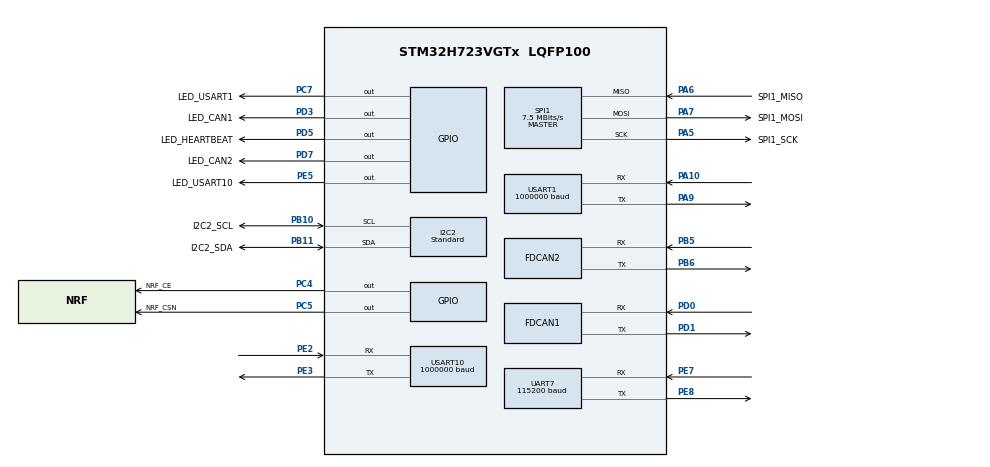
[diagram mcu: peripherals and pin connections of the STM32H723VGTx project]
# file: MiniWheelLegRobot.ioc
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CORTEX_M7.CPU_DCache=Disabled
CORTEX_M7.CPU_ICache=Enabled
Dma.Request0=UART7_RX
Dma.UART7_RX.0.Direction=DMA_PERIPH_TO_MEMORY
Dma.UART7_RX.0.EventEnable=DISABLE
Dma.UART7_RX.0.FIFOMode=DMA_FIFOMODE_DISABLE
Dma.UART7_RX.0.Instance=DMA1_Stream7
Dma.UART7_RX.0.MemDataAlignment=DMA_MDATAALIGN_BYTE
Dma.UART7_RX.0.MemInc=DMA_MINC_ENABLE
Dma.UART7_RX.0.Mode=DMA_NORMAL
Dma.UART7_RX.0.PeriphDataAlignment=DMA_PDATAALIGN_BYTE
Dma.UART7_RX.0.PeriphInc=DMA_PINC_DISABLE
Dma.UART7_RX.0.Polarity=HAL_DMAMUX_REQ_GEN_RISING
Dma.UART7_RX.0.Priority=DMA_PRIORITY_HIGH
Dma.UART7_RX.0.RequestNumber=1
Dma.UART7_RX.0.SignalID=NONE
Dma.UART7_RX.0.SyncEnable=DISABLE
Dma.UART7_RX.0.SyncPolarity=HAL_DMAMUX_SYNC_NO_EVENT
Dma.UART7_RX.0.SyncRequestNumber=1
Dma.UART7_RX.0.SyncSignalID=NONE
FDCAN1.AutoRetransmission=ENABLE
FDCAN1.CalculateBaudRateNominal=1000000
FDCAN1.CalculateTimeBitNominal=1000
FDCAN1.CalculateTimeQuantumNominal=12.5
FDCAN1.DataPrescaler=1
FDCAN1.DataTimeSeg1=59
FDCAN1.DataTimeSeg2=20
FDCAN1.ExtFiltersNbr=0
FDCAN1.MessageRAMOffset=0
FDCAN1.NominalPrescaler=1
FDCAN1.NominalSyncJumpWidth=20
FDCAN1.NominalTimeSeg1=59
FDCAN1.NominalTimeSeg2=20
FDCAN1.DataSyncJumpWidth=20
FDCAN1.RxFifo0ElmtSize=FDCAN_DATA_BYTES_8
FDCAN1.RxFifo0ElmtsNbr=16
FDCAN1.StdFiltersNbr=1
FDCAN1.TxElmtSize=FDCAN_DATA_BYTES_8
FDCAN1.TxFifoQueueElmtsNbr=8
FDCAN2.AutoRetransmission=ENABLE
FDCAN2.CalculateBaudRateNominal=1000000
FDCAN2.CalculateTimeBitNominal=1000
FDCAN2.CalculateTimeQuantumNominal=12.5
FDCAN2.DataPrescaler=1
FDCAN2.DataTimeSeg1=59
FDCAN2.DataTimeSeg2=20
FDCAN2.ExtFiltersNbr=0
FDCAN2.MessageRAMOffset=1280
FDCAN2.NominalPrescaler=1
FDCAN2.NominalSyncJumpWidth=20
FDCAN2.NominalTimeSeg1=59
FDCAN2.NominalTimeSeg2=20
FDCAN2.DataSyncJumpWidth=20
FDCAN2.RxFifo0ElmtSize=FDCAN_DATA_BYTES_8
FDCAN2.RxFifo0ElmtsNbr=16
FDCAN2.StdFiltersNbr=1
FDCAN2.TxElmtSize=FDCAN_DATA_BYTES_8
FDCAN2.TxFifoQueueElmtsNbr=8
FREERTOS.Tasks01=CtrlTask,56,512,StartCtrlTask,As external,NULL,Dynamic,NULL,NULL;CommandTask,40,384,StartCommandTask,As external,NULL,Dynamic,NULL,NULL;MonitorTask,24,384,StartMonitorTask,As external,NULL,Dynamic,NULL,NULL
I2C2.I2C_Speed_Mode=I2C_Standard
I2C2.Timing=0xB0522731
Mcu.Family=STM32H7
Mcu.Name=STM32H723VGTx
Mcu.Package=LQFP100
NVIC.DMA1_Stream7_IRQn=true\:5\:0\:true\:false\:true\:true\:false\:true\:true
NVIC.FDCAN1_IT0_IRQn=true\:5\:0\:true\:false\:true\:true\:true\:true\:true
NVIC.FDCAN2_IT0_IRQn=true\:5\:0\:true\:false\:true\:true\:true\:true\:true
NVIC.PriorityGroup=NVIC_PRIORITYGROUP_4
NVIC.TIM2_IRQn=true\:15\:0\:false\:false\:true\:false\:false\:true\:true
NVIC.TimeBase=TIM2_IRQn
NVIC.TimeBaseIP=TIM2
NVIC.UART7_IRQn=true\:5\:0\:true\:false\:true\:true\:true\:true\:true
PA10.Mode=Asynchronous
PA10.Signal=USART1_RX
PA13(JTMS/SWDIO).GPIO_Label=SWDIO
PA13(JTMS/SWDIO).Mode=Serial_Wire
PA13(JTMS/SWDIO).Signal=DEBUG_JTMS-SWDIO
PA14(JTCK/SWCLK).GPIO_Label=SWCLK
PA14(JTCK/SWCLK).Mode=Serial_Wire
PA14(JTCK/SWCLK).Signal=DEBUG_JTCK-SWCLK
PA5.GPIO_Label=SPI1_SCK
PA5.Mode=Full_Duplex_Master
PA5.Signal=SPI1_SCK
PA6.GPIO_Label=SPI1_MISO
PA6.Mode=Full_Duplex_Master
PA6.Signal=SPI1_MISO
PA7.GPIO_Label=SPI1_MOSI
PA7.Mode=Full_Duplex_Master
PA7.Signal=SPI1_MOSI
PA9.Mode=Asynchronous
PA9.Signal=USART1_TX
PB10.GPIO_Label=I2C2_SCL
PB10.Mode=I2C
PB10.Signal=I2C2_SCL
PB11.GPIO_Label=I2C2_SDA
PB11.Mode=I2C
PB11.Signal=I2C2_SDA
PB5.Mode=FDCAN_Activate
PB5.Signal=FDCAN2_RX
PB6.Mode=FDCAN_Activate
PB6.Signal=FDCAN2_TX
PC4.GPIO_Label=NRF_CE
PC4.GPIO_Speed=GPIO_SPEED_FREQ_HIGH
PC4.PinState=GPIO_PIN_RESET
PC4.Signal=GPIO_Output
PC5.GPIO_Label=NRF_CSN
PC5.GPIO_Speed=GPIO_SPEED_FREQ_HIGH
PC5.PinState=GPIO_PIN_SET
PC5.Signal=GPIO_Output
PC7.GPIO_Label=LED_USART1
PC7.GPIO_Speed=GPIO_SPEED_FREQ_LOW
PC7.PinState=GPIO_PIN_RESET
PC7.Signal=GPIO_Output
PD0.Mode=FDCAN_Activate
PD0.Signal=FDCAN1_RX
PD1.Mode=FDCAN_Activate
PD1.Signal=FDCAN1_TX
PD3.GPIO_Label=LED_CAN1
PD3.GPIO_Speed=GPIO_SPEED_FREQ_LOW
PD3.PinState=GPIO_PIN_RESET
PD3.Signal=GPIO_Output
PD5.GPIO_Label=LED_HEARTBEAT
PD5.GPIO_Speed=GPIO_SPEED_FREQ_LOW
PD5.PinState=GPIO_PIN_RESET
PD5.Signal=GPIO_Output
PD7.GPIO_Label=LED_CAN2
PD7.GPIO_Speed=GPIO_SPEED_FREQ_LOW
PD7.PinState=GPIO_PIN_RESET
PD7.Signal=GPIO_Output
PE2.Mode=Asynchronous
PE2.Signal=USART10_RX
PE3.Mode=Asynchronous
PE3.Signal=USART10_TX
PE5.GPIO_Label=LED_USART10
PE5.GPIO_Speed=GPIO_SPEED_FREQ_LOW
PE5.PinState=GPIO_PIN_RESET
PE5.Signal=GPIO_Output
PE7.Mode=Asynchronous
PE7.Signal=UART7_RX
PE8.Mode=Asynchronous
PE8.Signal=UART7_TX
PH0-OSC_IN.Mode=HSE-External-Oscillator
PH0-OSC_IN.Signal=RCC_OSC_IN
PH1-OSC_OUT.Mode=HSE-External-Oscillator
PH1-OSC_OUT.Signal=RCC_OSC_OUT
ProjectManager.HeapSize=0x2000
ProjectManager.StackSize=0x2000
ProjectManager.TargetToolchain=MDK-ARM
RCC.APB1Freq_Value=120000000
RCC.APB2Freq_Value=120000000
RCC.APB3Freq_Value=120000000
RCC.APB4Freq_Value=120000000
RCC.CortexFreq_Value=480000000
RCC.D1PPRE=RCC_APB3_DIV2
RCC.D2PPRE1=RCC_APB1_DIV2
RCC.D2PPRE2=RCC_APB2_DIV2
RCC.D3PPRE=RCC_APB4_DIV2
RCC.DIVM1=2
RCC.DIVM2=24
RCC.DIVN1=40
RCC.DIVN2=200
RCC.DIVP1=1
RCC.DIVP2=4
RCC.DIVQ1=6
RCC.FDCANCLockSelection=RCC_FDCANCLKSOURCE_PLL
RCC.HCLKFreq_Value=240000000
RCC.HPRE=RCC_HCLK_DIV2
RCC.HSE_VALUE=24000000
RCC.PLL1_VCO_SEL-AdvancedSettings=RCC_PLL1VCOWIDE
RCC.PLL2FRACN=0
RCC.PLLFRACN=0
RCC.PLLSourceVirtual=RCC_PLLSOURCE_HSE
RCC.SYSCLKFreq_VALUE=480000000
RCC.SYSCLKSource=RCC_SYSCLKSOURCE_PLLCLK
SPI1.BaudRatePrescaler=SPI_BAUDRATEPRESCALER_32
SPI1.CalculateBaudRate=7.5 MBits/s
SPI1.DataSize=SPI_DATASIZE_8BIT
SPI1.Direction=SPI_DIRECTION_2LINES
SPI1.Mode=SPI_MODE_MASTER
SPI1.NSSPMode=SPI_NSS_PULSE_DISABLE
SPI1.VirtualType=VM_MASTER
UART7.BaudRate=115200
UART7.VirtualMode=Asynchronous
USART1.BaudRate=1000000
USART1.VirtualMode=Asynchronous
USART10.BaudRate=1000000
USART10.VirtualMode=Asynchronous
VP_FREERTOS_VS_CMSIS_V2.Mode=CMSIS_V2
VP_MEMORYMAP_VS_MEMORYMAP.Mode=CurAppReg
VP_SYS_VS_tim2.Mode=TIM2
board=custom

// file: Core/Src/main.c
/* USER CODE BEGIN Header */
/**
 ******************************************************************************
 * @file           : main.c
 * @brief          : Main program body
 ******************************************************************************
 * @attention
 *
 * Copyright (c) 2025 STMicroelectronics.
 * All rights reserved.
 *
 * This software is licensed under terms that can be found in the LICENSE file
 * in the root directory of this software component.
 * If no LICENSE file comes with this software, it is provided AS-IS.
 *
 ******************************************************************************
 */
/* USER CODE END Header */
#include "main.h"
#include "cmsis_os.h"
#include "dma.h"
#include "fdcan.h"
#include "i2c.h"
#include "iwdg.h"
#include "spi.h"
#include "usart.h"
#include "gpio.h"

/* USER CODE BEGIN Includes */
#include "mini_robot_app.h"
/* USER CODE END Includes */

void SystemClock_Config(void);
void PeriphCommonClock_Config(void);
void MX_FREERTOS_Init(void);

int main(void)
{

  /* Enable the CPU Cache */

  /* Enable I-Cache---------------------------------------------------------*/
  SCB_EnableICache();

  /* MCU Configuration--------------------------------------------------------*/

  /* Reset of all peripherals, Initializes the Flash interface and the Systick. */
  HAL_Init();

  /* Configure the system clock */
  SystemClock_Config();

  /* Configure the peripherals common clocks */
  PeriphCommonClock_Config();

  /* Initialize all configured peripherals */
  MX_GPIO_Init();
  MX_DMA_Init();
  MX_FDCAN1_Init();
  MX_FDCAN2_Init();
  MX_I2C2_Init();
  MX_SPI1_Init();
  MX_USART1_UART_Init();
  MX_USART10_UART_Init();
  MX_UART7_Init();
#if MINI_IWDG_ENABLE
  MX_IWDG1_Init();
#endif
  /* USER CODE BEGIN 2 */
  MiniRobot_Init();

  /* USER CODE END 2 */

  /* Init scheduler */
  osKernelInitialize();  /* Call init function for freertos objects (in cmsis_os2.c) */
  MX_FREERTOS_Init();

  /* Start scheduler */
  osKernelStart();

  /* We should never get here as control is now taken by the scheduler */

  /* Infinite loop */
  /* USER CODE BEGIN WHILE */
  while (1)
  {
    /* USER CODE END WHI LE */

  }
}

void SystemClock_Config(void)
{
  RCC_OscInitTypeDef RCC_OscInitStruct = {0};
  RCC_ClkInitTypeDef RCC_ClkInitStruct = {0};

  /** Supply configuration update enable
  */
  HAL_PWREx_ConfigSupply(PWR_LDO_SUPPLY);

  /** Configure the main internal regulator output voltage
  */
  __HAL_PWR_VOLTAGESCALING_CONFIG(PWR_REGULATOR_VOLTAGE_SCALE0);

  while(!__HAL_PWR_GET_FLAG(PWR_FLAG_VOSRDY)) {}

  /** Initializes the RCC Oscillators according to the specified parameters
  * in the RCC_OscInitTypeDef structure.
  */
  RCC_OscInitStruct.OscillatorType = RCC_OSCILLATORTYPE_LSI|RCC_OSCILLATORTYPE_HSE;
  RCC_OscInitStruct.HSEState = RCC_HSE_ON;
  RCC_OscInitStruct.LSIState = RCC_LSI_ON;
  RCC_OscInitStruct.PLL.PLLState = RCC_PLL_ON;
  RCC_OscInitStruct.PLL.PLLSource = RCC_PLLSOURCE_HSE;
  RCC_OscInitStruct.PLL.PLLM = 2;
  RCC_OscInitStruct.PLL.PLLN = 40;
  RCC_OscInitStruct.PLL.PLLP = 1;
  RCC_OscInitStruct.PLL.PLLQ = 6;
  RCC_OscInitStruct.PLL.PLLR = 2;
  RCC_OscInitStruct.PLL.PLLRGE = RCC_PLL1VCIRANGE_3;
  RCC_OscInitStruct.PLL.PLLVCOSEL = RCC_PLL1VCOWIDE;
  RCC_OscInitStruct.PLL.PLLFRACN = 0;
  if (HAL_RCC_OscConfig(&RCC_OscInitStruct) != HAL_OK)
  {
    Error_Handler();
  }

  /** Initializes the CPU, AHB and APB buses clocks
  */
  RCC_ClkInitStruct.ClockType = RCC_CLOCKTYPE_HCLK|RCC_CLOCKTYPE_SYSCLK
                              |RCC_CLOCKTYPE_PCLK1|RCC_CLOCKTYPE_PCLK2
                              |RCC_CLOCKTYPE_D3PCLK1|RCC_CLOCKTYPE_D1PCLK1;
  RCC_ClkInitStruct.SYSCLKSource = RCC_SYSCLKSOURCE_PLLCLK;
  RCC_ClkInitStruct.SYSCLKDivider = RCC_SYSCLK_DIV1;
  RCC_ClkInitStruct.AHBCLKDivider = RCC_HCLK_DIV2;
  RCC_ClkInitStruct.APB3CLKDivider = RCC_APB3_DIV2;
  RCC_ClkInitStruct.APB1CLKDivider = RCC_APB1_DIV2;
  RCC_ClkInitStruct.APB2CLKDivider = RCC_APB2_DIV2;
  RCC_ClkInitStruct.APB4CLKDivider = RCC_APB4_DIV2;

  if (HAL_RCC_ClockConfig(&RCC_ClkInitStruct, FLASH_LATENCY_3) != HAL_OK)
  {
    Error_Handler();
  }
}

void PeriphCommonClock_Config(void)
{
  RCC_PeriphCLKInitTypeDef PeriphClkInitStruct = {0};

  /** Initializes the peripherals clock
  */
  PeriphClkInitStruct.PeriphClockSelection = RCC_PERIPHCLK_FDCAN;
  PeriphClkInitStruct.PLL2.PLL2M = 24;
  PeriphClkInitStruct.PLL2.PLL2N = 200;
  PeriphClkInitStruct.PLL2.PLL2P = 4;
  PeriphClkInitStruct.PLL2.PLL2Q = 2;
  PeriphClkInitStruct.PLL2.PLL2R = 2;
  PeriphClkInitStruct.PLL2.PLL2RGE = RCC_PLL2VCIRANGE_0;
  PeriphClkInitStruct.PLL2.PLL2VCOSEL = RCC_PLL2VCOMEDIUM;
  PeriphClkInitStruct.PLL2.PLL2FRACN = 0;
  PeriphClkInitStruct.FdcanClockSelection = RCC_FDCANCLKSOURCE_PLL;
  if (HAL_RCCEx_PeriphCLKConfig(&PeriphClkInitStruct) != HAL_OK)
  {
    Error_Handler();
  }
}

void HAL_TIM_PeriodElapsedCallback(TIM_HandleTypeDef *htim)
{
  if (htim->Instance == TIM2)
  {
    HAL_IncTick();
  }
}

void Error_Handler(void)
{
  __disable_irq();
  while (1)
  {
  }
}

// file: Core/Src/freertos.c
#include "FreeRTOS.h"
#include "cmsis_os.h"
#include "main.h"
#include "task.h"

osThreadId_t CtrlTaskHandle;
osThreadId_t CommandTaskHandle;
osThreadId_t MonitorTaskHandle;

static const osThreadAttr_t CtrlTask_attributes = {
    .name = "CtrlTask",
    .stack_size = 512U * 4U,
    .priority = (osPriority_t)osPriorityRealtime,
};

static const osThreadAttr_t CommandTask_attributes = {
    .name = "CommandTask",
    .stack_size = 384U * 4U,
    .priority = (osPriority_t)osPriorityAboveNormal,
};

static const osThreadAttr_t MonitorTask_attributes = {
    .name = "MonitorTask",
    .stack_size = 384U * 4U,
    .priority = (osPriority_t)osPriorityNormal,
};

void StartCtrlTask(void *argument);
void StartCommandTask(void *argument);
void StartMonitorTask(void *argument);

void MX_FREERTOS_Init(void)
{
    CtrlTaskHandle = osThreadNew(StartCtrlTask, NULL, &CtrlTask_attributes);
    CommandTaskHandle = osThreadNew(StartCommandTask, NULL, &CommandTask_attributes);
    MonitorTaskHandle = osThreadNew(StartMonitorTask, NULL, &MonitorTask_attributes);
}
